# ADC1_0.0 register map
Vendor: Texas Instruments
Peripheral module from a debugger description file (folder mspm33c321x).
Registers are 32-bit, read-write, no defined reset value unless marked. A register's access mark holds for its fields unless they carry their own. Offsets are as the file gives them; lines under a group give offsets from that group; [hi:lo] are bit positions; {n}, {i} and the like mark numbered series; 'fields as' and 'values as' point back to an identical list; <NAME> marks a mode.

## ADC1 (part 1 of 2)
{0x400+4i} HSADC1_FSUB_{i} (i=0..3) — Subscriber Port {i}
  [3:0] CHANID — 0 = disconnected. 1-15 = connected to channelID = CHANID.
    0=MNIMUM (0 is an allowed value, signifying that the event is unconnected); 0=UNCONNECTED (A value of 0 specifies that the event is not connected); 15=MAXIMUM (Consult your device datasheet as the actual allowed maximum may be less than 15.)
{0x444+4i} HSADC1_FPUB_{i} (i=0..3) — Publisher port {i}
  fields as HSADC1_FSUB_0
0x800 HSADC1_GPRCM group
  0x00 HSADC1_PWREN — Power enable
    [0] ENABLE — Enable the power
      0=DISABLE (Disable Power); 1=ENABLE (Enable Power)
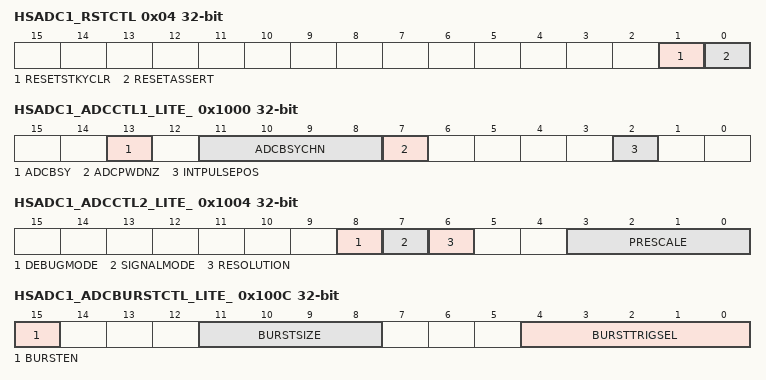
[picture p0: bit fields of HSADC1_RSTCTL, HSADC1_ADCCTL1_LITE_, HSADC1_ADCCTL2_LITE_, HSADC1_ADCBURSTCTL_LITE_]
  0x04 HSADC1_RSTCTL — Reset Control
    [1] RESETSTKYCLR — Clear the RESETSTKY bit in the STAT register
      0=NOP (Writing 0 has no effect); 1=CLR (Clear reset sticky bit)
    [0] RESETASSERT — Assert reset to the peripheral
      0=NOP (Writing 0 has no effect); 1=ASSERT (Assert reset)
  0x14 HSADC1_STAT ro — Status Register
    [16] RESETSTKYCLR — This bit indicates, if the peripheral was reset, since this bit was cleared by RESETSTKYCLR in the RSTCTL register
      0=NORES (The peripheral has not been reset since this bit was last cleared by RESETSTKYCLR in the RSTCTL register); 1=RESET (The peripheral was reset since the last bit clear)
0x1000 HSADC1_ADCCTL1_LITE_ access per field — ADC Control 1 Register
  [13] ADCBSY ro — ADC Busy. Set when ADC SOC is generated, cleared by hardware four ADC clocks after negative edge of S/H pulse. Used by the ADC state machine to determine if ADC is available to sample. #br# #br# 0 ADC is available to sample next channel #br# 1 ADC is busy and cannot sample another channel
  [11:8] ADCBSYCHN ro — ADC Busy Channel. Set when an ADC Start of Conversion (SOC) is generated. #br#When ADCBSY=0: holds the value of the last converted SOC #br#When ADCBSY=1: reflects the SOC currently being processed #br# 0h SOC0 is currently processing or was last SOC converted #br# 1h SOC1 is currently processing or was last SOC converted #br# 2h SOC2 is currently processing or was last SOC converted #br# 3h SOC3 is currently processing or was last SOC converted #br# 4h SOC4 is currently processing or was last SOC converted #br# 5h SOC5 is currently processing or was last SOC converted #br# 6h SOC6 is currently processing or was last SOC converted #br# 7h SOC7 is currently processing or was last SOC converted #br# 8h SOC8 is currently processing or was last SOC converted #br# 9h SOC9 is currently processing or was last SOC converted #br# Ah SOC10 is currently processing or was last SOC converted #br# Bh SOC11 is currently processing or was last SOC converted #br# Ch SOC12 is currently processing or was last SOC converted #br# Dh SOC13 is currently processing or was last SOC converted #br# Eh SOC14 is currently processing or was last SOC converted #br# Fh SOC15 is currently processing or was last SOC converted
  [7] ADCPWDNZ rw — ADC Power Down (active low). This bit controls the power up and power down of all the analog circuitry inside the analog core. #br# #br# 0 All analog circuitry inside the core is powered down #br# 1 All analog circuitry inside the core is powered up
  [2] INTPULSEPOS rw — ADC Interrupt Pulse Position. #br# #br# 0 Interrupt pulse generation occurs when ADC begins conversion (at the end of the acquisition window) plus a number of SYSCLK cycles as specified in the ADCINTCYCLE.OFFSET register. #br# 1 Interrupt pulse generation occurs at the end of the conversion, 1 cycle prior to the ADC result latching into its result register
0x1004 HSADC1_ADCCTL2_LITE_ — ADC Control 2 Register
  [8] DEBUGMODE — ADC Clocking Mode. Selects the number of ADCCLK pulses to be generated to the converter. #br# 0 Default mode - Generate only sufficient number of clocks based on Resolution and Sample Cap reset. #br# 1 Debug mode - Generate 2 additional ADCCLK pulses for every conversion.
  [7] SIGNALMODE — SOC Signaling Mode. Selects the input mode of the converter. Use the AdcSetMode function to change the signal mode. #br# 0 Single-ended #br# 1 Differential
  [6] RESOLUTION — SOC Conversion Resolution. Selects the resolution of the converter. Use the AdcSetMode function to change the resolution. #br# 0 12-bit resolution #br# 1 16-bit resolution
  [3:0] PRESCALE — ADC Clock Prescaler. #br# 0000 ADCCLK = Input Clock / 1.0 #br# 0001 ADCCLK = Input Clock / 1.5 #br# 0010 ADCCLK = Input Clock / 2.0 #br# 0011 ADCCLK = Input Clock / 2.5 #br# 0100 ADCCLK = Input Clock / 3.0 #br# 0101 ADCCLK = Input Clock / 3.5 #br# 0110 ADCCLK = Input Clock / 4.0 #br# 0111 ADCCLK = Input Clock / 4.5 #br# 1000 ADCCLK = Input Clock / 5.0 #br# 1001 ADCCLK = Input Clock / 5.5 #br# 1010 ADCCLK = Input Clock / 6.0 #br# 1011 ADCCLK = Input Clock / 6.5 #br# 1100 ADCCLK = Input Clock / 7.0 #br# 1101 ADCCLK = Input Clock / 7.5 #br# 1110 ADCCLK = Input Clock / 8.0 #br# 1111 ADCCLK = Input Clock / 8.5
0x100C HSADC1_ADCBURSTCTL_LITE_ — ADC Burst Control Register
  [15] BURSTEN — SOC Burst Mode Enable. This bit enables the SOC Burst Mode of operation. #br# #br# 0 Burst mode is disabled. #br# 1 Burst mode is enabled.
  [11:8] BURSTSIZE — SOC Burst Size Select. This bit field determines how many SOCs are converted when a burst conversion sequence is started. The first SOC converted is defined by the round robin pointer, which is advanced as each SOC is converted. #br# #br# 0h 1 SOC converted #br# 1h 2 SOCs converted #br# 2h 3 SOCs converted #br# 3h 4 SOCs converted #br# 4h 5 SOCs converted #br# 5h 6 SOCs converted #br# 6h 7 SOCs converted #br# 7h 8 SOCs converted #br# 8h 9 SOCs converted #br# 9h 10 SOCs converted #br# Ah 11 SOCs converted #br# Bh 12 SOCs converted #br# Ch 13 SOCs converted #br# Dh 14 SOCs converted #br# Eh 15 SOCs converted #br# Fh 16 SOCs converted
  [4:0] BURSTTRIGSEL — SOC Burst Trigger Source Select. Configures which trigger will start a burst conversion sequence. #br# #br#Note: SOCFRC1 register can always be used to software trigger SOCs in addition to any hardware trigger configuration. #br# 00h BURSTTRIG0 - Software only #br# 01h - 3Fh - Hardware Triggers
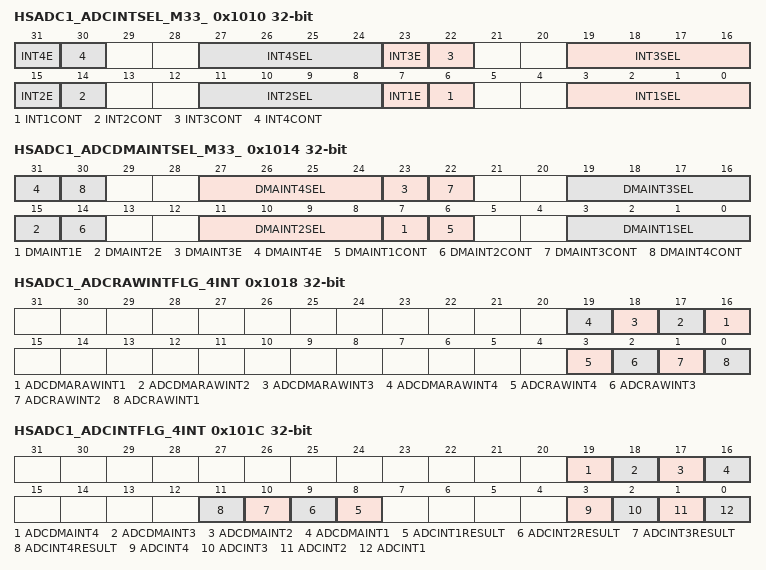
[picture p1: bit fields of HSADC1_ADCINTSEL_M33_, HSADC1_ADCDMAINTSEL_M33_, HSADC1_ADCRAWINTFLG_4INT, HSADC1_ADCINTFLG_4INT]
0x1010 HSADC1_ADCINTSEL_M33_ — ADC Interrupt 1, 2, 3 and 4 Selection Register
  [8n-1] INT{n}E (n=1..4) — ADCINT{n} Interrupt Enable #br# 0 ADCINT{n} is disabled #br# 1 ADCINT{n} is enabled
  [8n-2] INT{n}CONT (n=1..4) — ADCINT{n} Continue to Interrupt Mode #br# 0 No further ADCINT{n} pulses are generated until ADCINT{n} flag (in ADCINTFLG register) is cleared by user. #br# 1 ADCINT{n} pulses are generated whenever an EOC pulse is generated irrespective of whether the flag bit is cleared or not.
  [8n-5:8n-8] INT{n}SEL (n=1..4) — ADCINT{n} EOC Source Select #br# 00h EOC0 is trigger for ADCINT{n} #br# 01h EOC1 is trigger for ADCINT{n} #br# 02h EOC2 is trigger for ADCINT{n} #br# 03h EOC3 is trigger for ADCINT{n} #br# 04h EOC4 is trigger for ADCINT{n} #br# 05h EOC5 is trigger for ADCINT{n} #br# 06h EOC6 is trigger for ADCINT{n} #br# 07h EOC7 is trigger for ADCINT{n} #br# 08h EOC8 is trigger for ADCINT{n} #br# 09h EOC9 is trigger for ADCINT{n} #br# 0Ah EOC10 is trigger for ADCINT{n} #br# 0Bh EOC11 is trigger for ADCINT{n} #br# 0Ch EOC12 is trigger for ADCINT{n} #br# 0Dh EOC13 is trigger for ADCINT{n} #br# 0Eh EOC14 is trigger for ADCINT{n} #br# 0Fh EOC15 is trigger for ADCINT{n} #br# #br#Note : When oversampling is enabled, the end of the last oversampled coversion will trigger the interrupts #br#
0x1014 HSADC1_ADCDMAINTSEL_M33_ — ADC DMA Interrupt 1, 2, 3 and 4 Selection Register
  [8n-1] DMAINT{n}E (n=1..4) — ADCDMAINT{n} Interrupt Enable #br# 0 ADCDMAINT{n} is disabled #br# 1 ADCDMAINT{n} is enabled
  [8n-2] DMAINT{n}CONT (n=1..4) — ADCDMAINT{n} Continue to Interrupt Mode #br# 0 No further ADCDMAINT{n} pulses are generated until ADCDMAINT{n} flag (in ADCDMAINTFLG register) is cleared by user. #br# 1 ADCDMAINT{n} pulses are generated whenever an EOC pulse is generated irrespective of whether the flag bit is cleared or not.
  [27:24] DMAINT4SEL — ADCDMAINT4 EOC Source Select #br# 00h EOC0 is trigger for ADCDMAINT4 #br# 01h EOC1 is trigger for ADCDMAINT4 #br# 02h EOC2 is trigger for ADCDMAINT4 #br# 03h EOC3 is trigger for ADCDMAINT4 #br# 04h EOC4 is trigger for ADCDMAINT4 #br# 05h EOC5 is trigger for ADCDMAINT4 #br# 06h EOC6 is trigger for ADCDMAINT4 #br# 07h EOC7 is trigger for ADCDMAINT4 #br# 08h EOC8 is trigger for ADCDMAINT4 #br# 09h EOC9 is trigger for ADCDMAINT4 #br# 0Ah EOC10 is trigger for ADCDMAINT4 #br# 0Bh EOC11 is trigger for ADCDMAINT4 #br# 0Ch EOC12 is trigger for ADCDMAINT4 #br# 0Dh EOC13 is trigger for ADCDMAINT4 #br# 0Eh EOC14 is trigger for ADCDMAINT4 #br# 0Fh EOC15 is trigger for ADCDMAINT4 #br# #br#Note : When oversampling is enabled, the end of the last oversampled coversion will trigger the DMAINTerrupts #br#
  [19:16] DMAINT3SEL — ADCDMAINT3 EOC Source Select #br# 00h EOC0 is trigger for ADCDMAINT3 #br# 01h EOC1 is trigger for ADCDMAINT3 #br# 02h EOC2 is trigger for ADCDMAINT3 #br# 03h EOC3 is trigger for ADCDMAINT3 #br# 04h EOC4 is trigger for ADCDMAINT3 #br# 05h EOC5 is trigger for ADCDMAINT3 #br# 06h EOC6 is trigger for ADCDMAINT3 #br# 07h EOC7 is trigger for ADCDMAINT3 #br# 08h EOC8 is trigger for ADCDMAINT3 #br# 09h EOC9 is trigger for ADCDMAINT3 #br# 0Ah EOC10 is trigger for ADCDMAINT3 #br# 0Bh EOC11 is trigger for ADCDMAINT3 #br# 0Ch EOC12 is trigger for ADCDMAINT3 #br# 0Dh EOC13 is trigger for ADCDMAINT3 #br# 0Eh EOC14 is trigger for ADCDMAINT3 #br# 0Fh EOC15 is trigger for ADCDMAINT3 #br# #br#Note : When oversampling is enabled, the end of the last oversampled coversion will trigger the DMAINTerrupts #br#
  [11:8] DMAINT2SEL — ADCDMAINT2 EOC Source Select #br# 00h EOC0 is trigger for ADCDMAINT2 #br# 01h EOC1 is trigger for ADCDMAINT2 #br# 02h EOC2 is trigger for ADCDMAINT2 #br# 03h EOC3 is trigger for ADCDMAINT2 #br# 04h EOC4 is trigger for ADCDMAINT2 #br# 05h EOC5 is trigger for ADCDMAINT2 #br# 06h EOC6 is trigger for ADCDMAINT2 #br# 07h EOC7 is trigger for ADCDMAINT2 #br# 08h EOC8 is trigger for ADCDMAINT2 #br# 09h EOC9 is trigger for ADCDMAINT2 #br# 0Ah EOC10 is trigger for ADCDMAINT2 #br# 0Bh EOC11 is trigger for ADCDMAINT2 #br# 0Ch EOC12 is trigger for ADCDMAINT2 #br# 0Dh EOC13 is trigger for ADCDMAINT2 #br# 0Eh EOC14 is trigger for ADCDMAINT2 #br# 0Fh EOC15 is trigger for ADCDMAINT2 #br# #br#Note : When oversampling is enabled, the end of the last oversampled coversion will trigger the DMAINTerrupts #br#
  [3:0] DMAINT1SEL — ADCDMAINT1 EOC Source Select #br# 00h EOC0 is trigger for ADCDMAINT1 #br# 01h EOC1 is trigger for ADCDMAINT1 #br# 02h EOC2 is trigger for ADCDMAINT1 #br# 03h EOC3 is trigger for ADCDMAINT1 #br# 04h EOC4 is trigger for ADCDMAINT1 #br# 05h EOC5 is trigger for ADCDMAINT1 #br# 06h EOC6 is trigger for ADCDMAINT1 #br# 07h EOC7 is trigger for ADCDMAINT1 #br# 08h EOC8 is trigger for ADCDMAINT1 #br# 09h EOC9 is trigger for ADCDMAINT1 #br# 0Ah EOC10 is trigger for ADCDMAINT1 #br# 0Bh EOC11 is trigger for ADCDMAINT1 #br# 0Ch EOC12 is trigger for ADCDMAINT1 #br# 0Dh EOC13 is trigger for ADCDMAINT1 #br# 0Eh EOC14 is trigger for ADCDMAINT1 #br# 0Fh EOC15 is trigger for ADCDMAINT1 #br# #br#Note : When oversampling is enabled, the end of the last oversampled conversion will trigger the DMAINTerrupts #br#
0x1018 HSADC1_ADCRAWINTFLG_4INT ro — ADC Raw Interrupt Flag Register
  [n+15] ADCDMARAWINT{n} (n=1..4) — ADC DMA Raw Interrupt {n} Flag. Reading these flags indicates if the associated ADCDMAINT condition occurred. This flag will be set irrespective of corresponding DMAINTE setting #br# #br# 0 Selected EOC/OSINT event did not occur #br# 1 Selected EOC/OSINT event occurred #br# #br#Writing corresponding INTCLR bit in ADCINTFLGCLR register will clear this bit.
  [3] ADCRAWINT4 — ADC RAW Interrupt 4 Flag. Reading these flags indicates if the associated INT condition occurred. This flag will be set irrespective of corresponding INTE setting #br# #br# 0 Selected EOC/OSINT event did not occur #br# 1 Selected EOC/OSINT event occured #br# #br#Writing corresponding INTCLR bit in ADCINTFLGCLR register will clear this bit.
  [2] ADCRAWINT3 — ADC RAW Interrupt 3 Flag. Reading these flags indicates if the associated INT condition occurred. This flag will be set irrespective of corresponding INTE setting #br# #br# 0 Selected EOC/OSINT event did not occur #br# 1 Selected EOC/OSINT event occured #br# #br#Writing corresponding INTCLR bit in ADCINTFLGCLR register will clear this bit.
  [1] ADCRAWINT2 — ADC RAW Interrupt 2 Flag. Reading these flags indicates if the associated INT condition occurred. This flag will be set irrespective of corresponding INTE setting #br# #br# 0 Selected EOC/OSINT event did not occur #br# 1 Selected EOC/OSINT event occured #br# #br#Writing corresponding INTCLR bit in ADCINTFLGCLR register will clear this bit.
  [0] ADCRAWINT1 — ADC RAW Interrupt 1 Flag. Reading these flags indicates if the associated INT condition occurred. This flag will be set irrespective of corresponding INTE setting #br# #br# 0 Selected EOC/OSINT event did not occur #br# 1 Selected EOC/OSINT event occurred #br# #br#Writing corresponding INTCLR bit in ADCINTFLGCLR register will clear this bit.
0x101C HSADC1_ADCINTFLG_4INT ro — ADC Interrupt Flag Register
  [19] ADCDMAINT4 — ADC DMA Interrupt 4 Flag. Reading these flags indicates if the associated ADCDMAINT pulse was generated since the last clear. #br# #br# 0 No ADC DMA interru4pt pulse generated #br# 1 ADC DMA interrupt pulse generated #br# #br#If the ADC interrupt is placed in continue to interrupt mode (DMAINTSEL register) then further interrupt pulses are generated whenever a selected EOC event occurs even if the flag bit is set. If the continuous mode is not enabled, then no further interrupt pulses are generated until the user clears this flag bit using the ADCINTFLGCLR register. Rather, an ADC interrupt overflow event occurs in the ADCINTOVF register.
  [18] ADCDMAINT3 — ADC DMA Interrupt 3 Flag. Reading these flags indicates if the associated ADCDMAINT pulse was generated since the last clear. #br# #br# 0 No ADC DMA interrupt pulse generated #br# 1 ADC DMA interrupt pulse generated #br# #br#If the ADC interrupt is placed in continue to interrupt mode (DMAINTSEL register) then further interrupt pulses are generated whenever a selected EOC event occurs even if the flag bit is set. If the continuous mode is not enabled, then no further interrupt pulses are generated until the user clears this flag bit using the ADCINTFLGCLR register. Rather, an ADC interrupt overflow event occurs in the ADCINTOVF register.
  [17] ADCDMAINT2 — ADC DMA Interrupt 2 Flag. Reading these flags indicates if the associated ADCDMAINT pulse was generated since the last clear. #br# #br# 0 No ADC DMA interrupt pulse generated #br# 1 ADC DMA interrupt pulse generated #br# #br#If the ADC DMA interrupt is placed in continue to interrupt mode (DMAINTSEL register) then further interrupt pulses are generated whenever a selected EOC event occurs even if the flag bit is set. If the continuous mode is not enabled, then no further interrupt pulses are generated until the user clears this flag bit using the ADCINTFLGCLR register. Rather, an ADC interrupt overflow event occurs in the ADCINTOVF register.
  [16] ADCDMAINT1 — ADC DMA Interrupt 1 Flag. Reading these flags indicates if the associated ADCDMAINT pulse was generated since the last clear. #br# #br# 0 No ADC DMA interrupt pulse generated #br# 1 ADC DMA interrupt pulse generated #br# #br#If the ADC interrupt is placed in continue to interrupt mode (DMAINTSEL register) then further interrupt pulses are generated whenever a selected EOC event occurs even if the flag bit is set. If the continuous mode is not enabled, then no further interrupt pulses are generated until the user clears this flag bit using the ADCINTFLGCLR register. Rather, an ADC interrupt overflow event occurs in the ADCINTOVF register.
  [n+7] ADCINT{n}RESULT (n=1..4) — ADC Interrupt {n} Results Ready Flag. This flag is set when the conversions results associated with ADCINT{n} latch into the corresponding results register. #br# #br# 0 Conversion results have not latched #br# 1 Conversion results have latched #br# #br#This flag can be used in an ISR that is entered in early interrupt mode to ensure that the corresponding results are ready before proceeding to read the result register. #br# #br#This flag can be cleared via the ACK bit in the ADCINTFLGCLR that also clears the ADCINT{n} flag. #br# #br#In case results latch and this flag is already set, the corresponding flag in ADCINTOVF is NOT set. This flag does NOT have to be cleared in order for ADCINT ISRs to propagate to the PIE. #br# #br#In case the associated SOC is associated with a PPB or PPBs, the flag will not be set until all associated PPB results latch.
  [3] ADCINT4 — ADC Interrupt 4 Flag. Reading these flags indicates if the associated ADCINT pulse was generated since the last clear. #br# #br# 0 No ADC interrupt pulse generated #br# 1 ADC interrupt pulse generated #br# #br#If the ADC interrupt is placed in continue to interrupt mode (INTSEL register) then further interrupt pulses are generated whenever a selected EOC event occurs even if the flag bit is set. If the continuous mode is not enabled, then no further interrupt pulses are generated until the user clears this flag bit using the ADCINFLGCLR register. Rather, an ADC interrupt overflow event occurs in the ADCINTOVF register.
  [2] ADCINT3 — ADC Interrupt 3 Flag. Reading these flags indicates if the associated ADCINT pulse was generated since the last clear. #br# #br# 0 No ADC interrupt pulse generated #br# 1 ADC interrupt pulse generated #br# #br#If the ADC interrupt is placed in continue to interrupt mode (INTSEL register) then further interrupt pulses are generated whenever a selected EOC event occurs even if the flag bit is set. If the continuous mode is not enabled, then no further interrupt pulses are generated until the user clears this flag bit using the ADCINTFLGCLR register. Rather, an ADC interrupt overflow event occurs in the ADCINTOVF register.
  [1] ADCINT2 — ADC Interrupt 2 Flag. Reading these flags indicates if the associated ADCINT pulse was generated since the last clear. #br# #br# 0 No ADC interrupt pulse generated #br# 1 ADC interrupt pulse generated #br# #br#If the ADC interrupt is placed in continue to interrupt mode (INTSEL register) then further interrupt pulses are generated whenever a selected EOC event occurs even if the flag bit is set. If the continuous mode is not enabled, then no further interrupt pulses are generated until the user clears this flag bit using the ADCINTFLGCLR register. Rather, an ADC interrupt overflow event occurs in the ADCINTOVF register.
  [0] ADCINT1 — ADC Interrupt 1 Flag. Reading these flags indicates if the associated ADCINT pulse was generated since the last clear. #br# #br# 0 No ADC interrupt pulse generated #br# 1 ADC interrupt pulse generated #br# #br#If the ADC interrupt is placed in continue to interrupt mode (INTSEL register) then further interrupt pulses are generated whenever a selected EOC event occurs even if the flag bit is set. If the continuous mode is not enabled, then no further interrupt pulses are generated until the user clears this flag bit using the ADCINTFLGCLR register. Rather, an ADC interrupt overflow event occurs in the ADCINTOVF register.
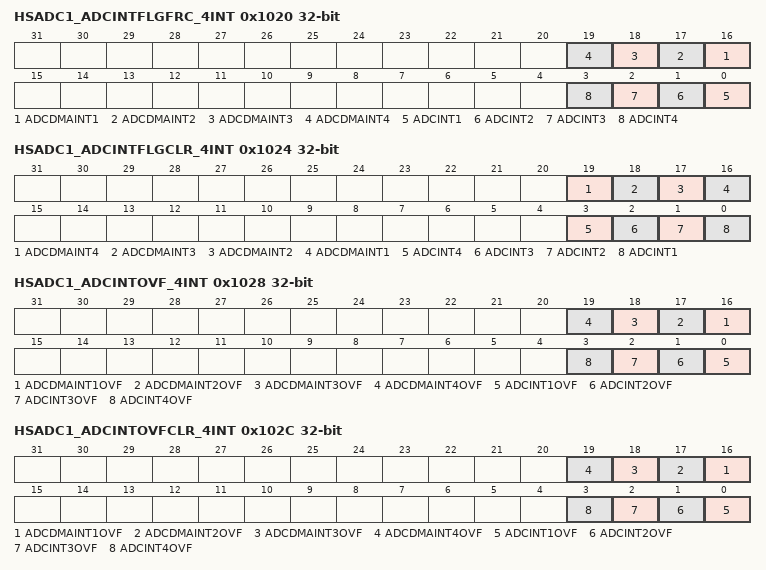
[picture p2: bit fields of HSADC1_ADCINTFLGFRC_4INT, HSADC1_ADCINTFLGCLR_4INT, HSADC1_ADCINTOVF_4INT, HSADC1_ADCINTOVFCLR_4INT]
0x1020 HSADC1_ADCINTFLGFRC_4INT — ADC Interrupt Flag Force Register
  [n+15] ADCDMAINT{n} (n=1..4) — ADC DMA interrupt {n} Flag Force. Reads return 0. #br# #br# 0 No action #br# 1 Forces ADCDMAINT{n} flags in the ADCINTFLG and ADCRAWINTFLG registers.
  [n-1] ADCINT{n} (n=1..4) — ADC Interrupt {n} Flag Force. Reads return 0. #br# #br# 0 No action #br# 1 Forces ADCINT{n} flags in the ADCINTFLG and ADCRAWINTFLG registers.
0x1024 HSADC1_ADCINTFLGCLR_4INT — ADC Interrupt Flag Clear Register
  [19] ADCDMAINT4 — ADC DMA Interrupt 4 Flag Clear. Reads return 0. #br# #br# 0 No action #br# 1 Clears ADDMACINT4 flags in the ADCINTFLG ,ADCRAWINTFLG registers. #br#If software sets the clear bit on the same cycle that hardware is trying to set the flag bit, then hardware has priority and the overflow bit will not be set
  [18] ADCDMAINT3 — ADC DMA Interrupt 3 Flag Clear. Reads return 0. #br# #br# 0 No action #br# 1 Clears ADDMACINT3 flags in the ADCINTFLG ,ADCRAWINTFLG registers. #br# If software sets the clear bit on the same cycle that hardware is trying to set the flag bit, then hardware has priority and the overflow bit will not be set
  [17] ADCDMAINT2 — ADC DMA Interrupt 2 Flag Clear. Reads return 0. #br# #br# 0 No action #br# 1 Clears ADDMACINT2 flags in the ADCINTFLG ,ADCRAWINTFLG registers. #br#If software sets the clear bit on the same cycle that hardware is trying to set the flag bit, then hardware has priority and the overflow bit will not be set
  [16] ADCDMAINT1 — ADC DMA Interrupt 1 Flag Clear. Reads return 0. #br# #br# 0 No action #br# 1 Clears ADDMACINT1 flags in the ADCINTFLG ,ADCRAWINTFLG registers. #br#If software sets the clear bit on the same cycle that hardware is trying to set the flag bit, then hardware has priority and the overflow bit will not be set
  [3] ADCINT4 — ADC Interrupt 4 Flag Clear. Reads return 0. #br# #br# 0 No action #br# 1 Clears ADCINT4 and ADCINT4RESULT flags in the ADCINTFLG,, ADCRAWINTFLG registers. #br#If software sets the clear bit on the same cycle that hardware is trying to set the flag bit, then hardware has priority and the overflow bit will not be set
  [2] ADCINT3 — ADC Interrupt 3 Flag Clear. Reads return 0. #br# #br# 0 No action #br# 1 Clears ADCINT3 and ADCINT3RESULT flags in the ADCINTFLG, ADCRAWINTFLG registers. #br# If software sets the clear bit on the same cycle that hardware is trying to set the flag bit, then hardware has priority and the overflow bit will not be set
  [1] ADCINT2 — ADC Interrupt 2 Flag Clear. Reads return 0. #br# #br# 0 No action #br# 1 Clears ADCINT2 and ADCINT2RESULT flags in the ADCINTFLG, ADCRAWINTFLG registers. If software sets the clear bit on the same cycle that hardware is trying to set the flag bit, then hardware has priority and the overflow bit will not be set
  [0] ADCINT1 — ADC Interrupt 1 Flag Clear. Reads return 0. #br# #br# 0 No action #br# 1 Clears ADCINT1 and ADCINT1RESULT flags in the ADCINTFLG, ADCRAWINTFLG registers. #br#If software sets the clear bit on the same cycle that hardware is trying to set the flag bit, then hardware has priority and the overflow bit will not be set
0x1028 HSADC1_ADCINTOVF_4INT ro — ADC Interrupt Overflow Register
  [n+15] ADCDMAINT{n}OVF (n=1..4) — ADC DMA Interrupt {n} Overflow Flags #br# #br#Indicates if an overflow occurred when generating ADCINT pulses. If the respective ADCINTFLG bit is set and a selected additional EOC trigger is generated, then an overflow condition occurs. #br# #br# 0 No ADC DMA Interrupt overflow event detected. #br# 1 ADC DMA Interrupt overflow event detected. #br# #br#The overflow bit does not care about the continuous mode bit state. An overflow condition is generated irrespective of this mode selection.
  [n-1] ADCINT{n}OVF (n=1..4) — ADC Interrupt {n} Overflow Flags #br# #br#Indicates if an overflow occurred when generating ADCINT pulses. If the respective ADCINTFLG bit is set and a selected additional EOC trigger is generated, then an overflow condition occurs. #br# #br# 0 No ADC interrupt overflow event detected. #br# 1 ADC Interrupt overflow event detected. #br# #br#The overflow bit does not care about the continuous mode bit state. An overflow condition is generated irrespective of this mode selection.
0x102C HSADC1_ADCINTOVFCLR_4INT — ADC Interrupt Overflow Clear Register
  [n+15] ADCDMAINT{n}OVF (n=1..4) — ADC DMA Interrupt {n} Overflow Clear Bits #br# #br# 0 No action. #br# 1 Clears the respective overflow bit in the ADCINTOVF register. If software tries to set this bit on the same clock cycle that hardware tries to set the overflow bit in the ADCINTOVF register, then hardware has priority and the ADCINTOVF bit will be set.
  [n-1] ADCINT{n}OVF (n=1..4) — ADC Interrupt {n} Overflow Clear Bits #br# #br# 0 No action. #br# 1 Clears the respective overflow bit in the ADCINTOVF register. If software tries to set this bit on the same clock cycle that hardware tries to set the overflow bit in the ADCINTOVF register, then hardware has priority and the ADCINTOVF bit will be set.
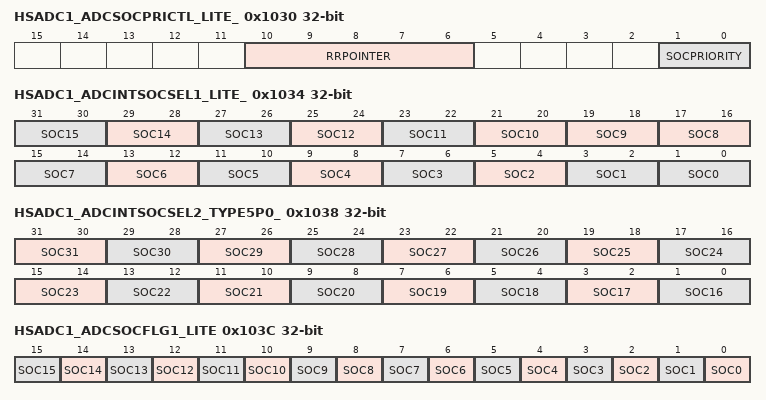
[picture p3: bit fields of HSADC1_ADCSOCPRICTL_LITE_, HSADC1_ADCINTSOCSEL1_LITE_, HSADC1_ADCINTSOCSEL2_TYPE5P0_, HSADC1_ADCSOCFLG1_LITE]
0x1030 HSADC1_ADCSOCPRICTL_LITE_ access per field — ADC SOC Priority Control Register
  [10:6] RRPOINTER ro — Round Robin Pointer. Holds the value of the last converted round robin SOCx to be used by the round robin scheme to determine order of conversions. #br# 00h SOC0 was last round robin SOC to convert, SOC1 is highest round robin priority. #br# 01h SOC1 was last round robin SOC to convert, SOC2 is highest round robin priority. #br# 02h SOC2 was last round robin SOC to convert, SOC3 is highest round robin priority. #br# 03h SOC3 was last round robin SOC to convert, SOC4 is highest round robin priority. #br# 04h SOC4 was last round robin SOC to convert, SOC5 is highest round robin priority. #br# 05h SOC5 was last round robin SOC to convert, SOC6 is highest round robin priority. #br# 06h SOC6 was last round robin SOC to convert, SOC7 is highest round robin priority. #br# 07h SOC7 was last round robin SOC to convert, SOC8 is highest round robin priority. #br# 08h SOC8 was last round robin SOC to convert, SOC9 is highest round robin priority. #br# 09h SOC9 was last round robin SOC to convert, SOC10 is highest round robin priority. #br# 0Ah SOC10 was last round robin SOC to convert, SOC11 is highest round robin priority. #br# 0Bh SOC11 was last round robin SOC to convert, SOC12 is highest round robin priority. #br# 0Ch SOC12 was last round robin SOC to convert, SOC13 is highest round robin priority. #br# 0Dh SOC13 was last round robin SOC to convert, SOC14 is highest round robin priority. #br# 0Eh SOC14 was last round robin SOC to convert, SOC15 is highest round robin priority. #br# 0Fh SOC15 was last round robin SOC to convert, SOC0 is highest round robin priority. #br# 10h Reset value to indicate no SOC has been converted. SOC0 is highest round robin priority. Set to this value when the ADC module is reset by SOFTPRES or when the ADCSOCPRICTL register is written. In the latter case, if a conversion is currently in progress, it will complete and then the new priority will take effect. #br#Others Invalid value.
  [1:0] SOCPRIORITY rw — SOC Priority #br#Determines the cutoff point for priority mode and round robin arbitration for SOCx #br# 0h SOC priority is handled in round robin mode for all channels. #br# 1h SOC0 is high priority, rest of channels are in round robin mode. #br# 2h SOC0-SOC1 are high priority, SOC2-SOC15 are in round robin mode. #br# 3h SOC0-SOC2 are high priority, SOC3-SOC15 are in round robin mode.
0x1034 HSADC1_ADCINTSOCSEL1_LITE_ — ADC Interrupt SOC Selection 1 Register
  [2n+1:2n] SOC{n} (n=10..15) — SOC{n} ADC Interrupt Trigger Select. Selects which, if any, ADCINT triggers SOC{n}. The trigger selected in this field is in addition to the TRIGSEL field in the ADCSOCxCTL register. #br# 00 No ADCINT will trigger SOC{n}. TRIGSEL field alone determines SOC{n} trigger. #br# 01 ADCINT1 will trigger SOC{n}. #br# 10 ADCINT2 will trigger SOC{n}. #br# 11 EOC{n-1} will trigger SOC{n}.
  [19:18] SOC9 — SOC9 ADC Interrupt Trigger Select. Selects which, if any, ADCINT triggers SOC9. The trigger selected in this field is in addition to the TRIGSEL field in the ADCSOCxCTL register. #br# 00 No ADCINT will trigger SOC9. TRIGSEL field alone determines SOC9 trigger. #br# 01 ADCINT1 will trigger SOC9. #br# 10 ADCINT2 will trigger SOC1. #br# 11 EOC8 will trigger SOC9.
  [2n+1:2n] SOC{n} (n=1..8) — SOC{n} ADC Interrupt Trigger Select. Selects which, if any, ADCINT triggers SOC{n}. The trigger selected in this field is in addition to the TRIGSEL field in the ADCSOCxCTL register. #br# 00 No ADCINT will trigger SOC{n}. TRIGSEL field alone determines SOC{n} trigger. #br# 01 ADCINT1 will trigger SOC{n}. #br# 10 ADCINT2 will trigger SOC{n}. #br# 11 EOC{n-1} will trigger SOC{n}.
  [1:0] SOC0 — SOC0 ADC Interrupt Trigger Select. Selects which, if any, ADCINT triggers SOC0. The trigger selected in this field is in addition to the TRIGSEL field in the ADCSOCxCTL register. #br# 00 No ADCINT will trigger SOC0. TRIGSEL field alone determines SOC0 trigger. #br# 01 ADCINT1 will trigger SOC0. #br# 10 ADCINT2 will trigger SOC0. #br# 11 EOC[N-1] will trigger SOC0. #br#N - Total number of SOCs supported
0x1038 HSADC1_ADCINTSOCSEL2_TYPE5P0_ — ADC Interrupt SOC Selection 2 Register
  [2n-31:2n-32] SOC{n} (n=17..31) — SOC{n} ADC Interrupt Trigger Select. Selects which, if any, ADCINT triggers SOC{n}. The trigger selected in this field is in addition to the TRIGSEL field in the ADCSOCxCTL register. #br# 00 No ADCINT will trigger SOC{n}. TRIGSEL field alone determines SOC0 trigger. #br# 01 ADCINT1 will trigger SOC{n}. #br# 10 ADCINT2 will trigger SOC{n}. #br# 11 Invalid selection.
  [1:0] SOC16 — SOC16 ADC Interrupt Trigger Select. Selects which, if any, ADCINT triggers SOC16. The trigger selected in this field is in addition to the TRIGSEL field in the ADCSOCxCTL register. #br# 00 No ADCINT will trigger SOC16. TRIGSEL field alone determines SOC16 trigger. #br# 01 ADCINT1 will trigger SOC16. #br# 10 ADCINT2 will trigger SOC16. #br# 11 Invalid selection.
0x103C HSADC1_ADCSOCFLG1_LITE ro — ADC SOC Flag 1 Register
  [n] SOC{n} (n=0..15) — SOC{n} Start of Conversion Flag. Indicates the state of SOC{n} conversions. #br# #br# 0 No sample pending for SOC{n}. #br# 1 Trigger has been received and sample is pending for SOC{n}. #br# #br#This bit will be automatically cleared when the SOC{n} conversion is started. If contention exists where this bit receives both a request to set and a request to clear on the same cycle, regardless of the source of either, this bit will be set and the request to clear will be ignored. In this case the overflow bit in the ADCSOCOVF1 register will not be affected regardless of whether this bit was previously set or not.
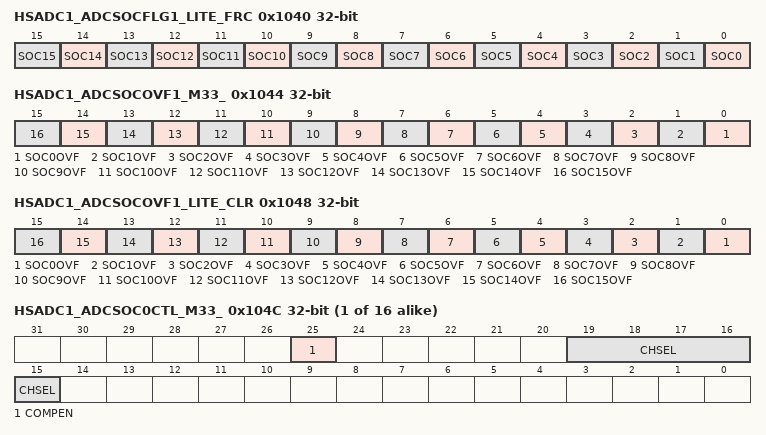
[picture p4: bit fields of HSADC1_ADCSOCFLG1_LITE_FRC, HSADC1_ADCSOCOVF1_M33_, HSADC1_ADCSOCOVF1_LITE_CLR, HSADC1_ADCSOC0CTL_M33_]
0x1040 HSADC1_ADCSOCFLG1_LITE_FRC — ADC SOC Force 1 Register
  [n] SOC{n} (n=0..15) — SOC{n} Force Start of Conversion Bit. Writing a 1 will force to 1 the SOC{n} flag in the ADCSOCFLG1 register. This can be used to initiate a software initiated conversion. Writes of 0 are ignored. This bit will always read as a 0. #br# #br# 0 No action. #br# 1 Force SOC{n} flag bit to 1. This will cause a conversion to start once priority is given to SOC{n}. #br# #br#If software tries to set this bit on the same clock cycle that hardware tries to clear the SOC{n} bit in the ADCSOCFLG1 register, then software has priority and the ADCSOCFLG1 bit will be set. In this case the overflow bit in the ADCSOCOVF1 register will not be affected regardless of whether the ADCSOCFLG1 bit was previously set or not.
0x1044 HSADC1_ADCSOCOVF1_M33_ ro — ADC SOC Overflow 1 Register
  [n] SOC{n}OVF (n=0..15) — SOC{n} Start of Conversion Overflow Flag. Indicates an SOC{n} event was generated in hardware while an existing SOC{n} event was already pending. #br# #br# 0 No SOC{n} event overflow. #br# 1 SOC{n} event overflow. #br# #br#An overflow condition does not stop SOC{n} events from being processed. It simply is an indication that a hardware trigger was missed.
0x1048 HSADC1_ADCSOCOVF1_LITE_CLR — ADC SOC Overflow Clear 1 Register
  [n] SOC{n}OVF (n=0..15) — SOC{n} Clear Start of Conversion Overflow Bit. Writing a 1 will clear the SOC{n} overflow flag in the ADCSOCOVF1 register. Writes of 0 are ignored. Reads will always return a 0. #br# #br# 0 No action. #br# 1 Clear SOC{n} overflow flag. #br# #br#If software tries to set this bit on the same clock cycle that hardware tries to set the overflow bit in the ADCSOCOVF1 register, then hardware has priority and the ADCSOCOVF1 bit will be set..
{0x104C+4i} HSADC1_ADCSOC{i}CTL_M33_ (i=0..15) — ADC SOC{i} Control Register
  [25] COMPEN — SOC{i} Threshold comparator enable.
  [19:15] CHSEL — SOC{i} Channel Select. Selects the channel to be converted when SOC{i} is received by the ADC. #br# 00h ADCIN0 #br# 01h ADCIN1 #br# 02h ADCIN2 #br# 03h ADCIN3 #br# ... #br# 1Dh ADCIN29 #br# 1Eh ADCIN30 #br# 1Fh ADCIN31
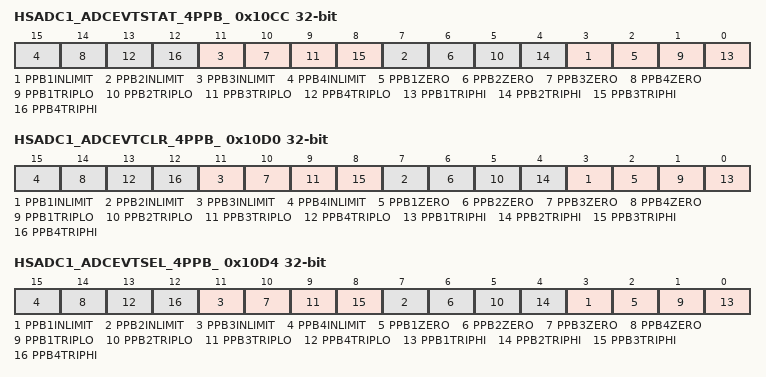
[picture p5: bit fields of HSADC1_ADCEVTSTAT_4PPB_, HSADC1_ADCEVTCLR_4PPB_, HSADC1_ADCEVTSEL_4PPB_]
0x10CC HSADC1_ADCEVTSTAT_4PPB_ ro — ADC Event Status Register
  [4n-1] PPB{n}INLIMIT (n=1..4) — Post Processing Block {n} Within trip limit Flag. When set indicates a digital compare within limit event has occurred. This will be set when the PPB result is either in between or equal to the TRIPHI and TRIPLO thresholds. #br# #br#Note: these bits are set even when the corresponding enable in ADCEVTINTSEL is not set. Because of this, an ISR may need to examine both the ADCEVTSTAT and ADCEVTINTSEL registers to determine the source of the interrupt. #br# #br#Note: If software sets the clear bit on the same cycle that hardware is trying to set the flag bit, then hardware has priority
  [4n-2] PPB{n}ZERO (n=1..4) — Post Processing Block {n} Zero Crossing Flag. When set indicates the ADCPPB{n}RESULT register has changed sign. This bit is gated by EOC signal. #br# #br#Note: these bits are set even when the corresponding enable in ADCEVTINTSEL is not set. Because of this, an ISR may need to examine both the ADCEVTSTAT and ADCEVTINTSEL registers to determine the source of the interrupt. #br# #br#Note: If software sets the clear bit on the same cycle that hardware is trying to set the flag bit, then hardware has priority
  [4n-3] PPB{n}TRIPLO (n=1..4) — Post Processing Block {n} Trip Low Flag. When set indicates a digital compare trip low event has occurred. #br# #br#Note: these bits are set even when the corresponding enable in ADCEVTINTSEL is not set. Because of this, an ISR may need to examine both the ADCEVTSTAT and ADCEVTINTSEL registers to determine the source of the interrupt. #br# #br#Note: If software sets the clear bit on the same cycle that hardware is trying to set the flag bit, then hardware has priority
  [4n-4] PPB{n}TRIPHI (n=1..4) — Post Processing Block {n} Trip High Flag. When set indicates a digital compare trip high event has occurred. #br# #br#Note: these bits are set even when the corresponding enable in ADCEVTINTSEL is not set. Because of this, an ISR may need to examine both the ADCEVTSTAT and ADCEVTINTSEL registers to determine the source of the interrupt. #br# #br#Note: If software sets the clear bit on the same cycle that hardware is trying to set the flag bit, then hardware has priority
0x10D0 HSADC1_ADCEVTCLR_4PPB_ — ADC Event Clear Register
  [4n-1] PPB{n}INLIMIT (n=1..4) — Post Processing Block {n} Within trip limit flag Clear, Clears the corresponding within trip limit flag in the ADCEVTSTAT register. #br# #br#Note: If software sets the clear bit on the same cycle that hardware is trying to set the flag bit, then hardware has priority
  [4n-2] PPB{n}ZERO (n=1..4) — Post Processing Block {n} Zero Crossing Clear. Clears the corresponding zero crossing flag in the ADCEVTSTAT register. #br# #br#Note: If software sets the clear bit on the same cycle that hardware is trying to set the flag bit, then hardware has priority
  [4n-3] PPB{n}TRIPLO (n=1..4) — Post Processing Block {n} Trip Low Clear. Clears the corresponding trip low flag in the ADCEVTSTAT register. #br# #br#Note: If software sets the clear bit on the same cycle that hardware is trying to set the flag bit, then hardware has priority
  [4n-4] PPB{n}TRIPHI (n=1..4) — Post Processing Block {n} Trip High Clear. Clears the corresponding trip high flag in the ADCEVTSTAT register. #br# #br#Note: If software sets the clear bit on the same cycle that hardware is trying to set the flag bit, then hardware has priority
0x10D4 HSADC1_ADCEVTSEL_4PPB_ — ADC Event Selection Register
  [4n-1] PPB{n}INLIMIT (n=1..4) — Post Processing Block {n} Within trip limit event enable. Setting this bit allows the corresponding rising zero crossing flag to activate the event signal to the PWM blocks. The flag must be cleared before it can produce additional events to the PWM blocks.
  [4n-2] PPB{n}ZERO (n=1..4) — Post Processing Block {n} Zero Crossing Event Enable. Setting this bit allows the corresponding rising zero crossing flag to activate the event signal to the PWM blocks. The flag must be cleared before it can produce additional events to the PWM blocks.
  [4n-3] PPB{n}TRIPLO (n=1..4) — Post Processing Block {n} Trip Low Event Enable. Setting this bit allows the corresponding rising trip low flag to activate the event signal to the PWM blocks. The flag must be cleared before it can produce additional events to the PWM blocks.
  [4n-4] PPB{n}TRIPHI (n=1..4) — Post Processing Block {n} Trip High Event Enable. Setting this bit allows the corresponding rising trip high flag to activate the event signal to the PWM blocks. The flag must be cleared before it can produce additional events to the PWM blocks.
